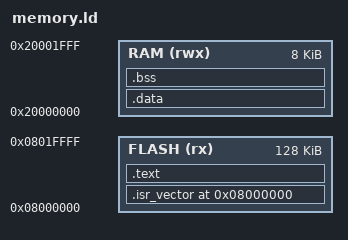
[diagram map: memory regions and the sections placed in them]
MEMORY
{
    FLASH (rx)  : ORIGIN = 0x08000000, LENGTH = 128K
    RAM   (rwx) : ORIGIN = 0x20000000, LENGTH = 8K
}

_estack = ORIGIN(RAM) + LENGTH(RAM);

ENTRY(Reset_Handler)

SECTIONS
{
    . = ORIGIN(FLASH);

    .isr_vector :
    {
        KEEP(*(.isr_vector))
    } > FLASH

    .text :
    {
        *(.text*)
        *(.rodata*)
    } > FLASH

    .data :
    {
        *(.data*)
    } > RAM

    .bss :
    {
        *(.bss*)
        *(COMMON)
    } > RAM
}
